VERSION "HIPBNYYYYYYYYYYYYYYYYYYYYYYYYYYYYYYYYYYYYY/4/%%%/4/'%**4YYY///"

NS_ :

BS_:

BU_:

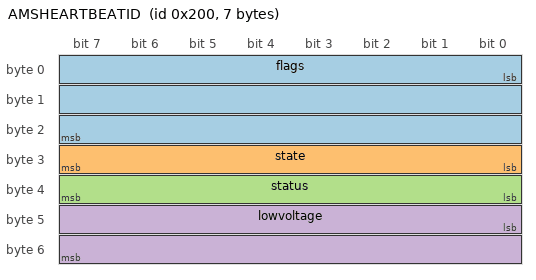
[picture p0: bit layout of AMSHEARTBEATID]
BO_ 512 AMSHEARTBEATID: 7 Vector__XXX
 SG_ flags : 0|24@1+ (1,0) [0|0] "" Vector__XXX
 SG_ state : 24|8@1+ (1,0) [0|0] "" Vector__XXX
 SG_ status : 32|8@1+ (1,0) [0|0] "" Vector__XXX
 SG_ lowvoltage : 40|16@1- (1,0) [0|0] "" Vector__XXX
